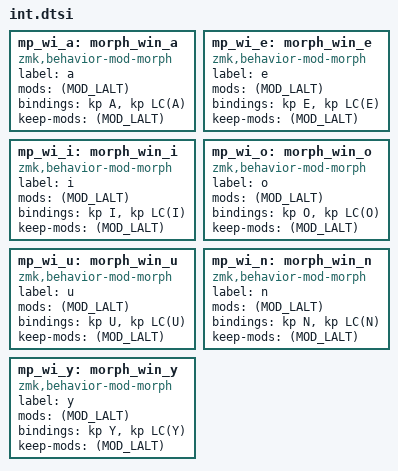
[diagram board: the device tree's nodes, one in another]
mp_wi_a: morph_win_a {
    compatible = "zmk,behavior-mod-morph";
    label = "a";
    #binding-cells = <0>;
    mods = <(MOD_LALT)>;
    bindings = <&kp A>, <&kp LC(A)>;
    keep-mods = <(MOD_LALT)>;
};

mp_wi_e: morph_win_e {
    compatible = "zmk,behavior-mod-morph";
    label = "e";
    #binding-cells = <0>;
    mods = <(MOD_LALT)>;
    bindings = <&kp E>, <&kp LC(E)>;
    keep-mods = <(MOD_LALT)>;
};

mp_wi_i: morph_win_i {
    compatible = "zmk,behavior-mod-morph";
    label = "i";
    #binding-cells = <0>;
    mods = <(MOD_LALT)>;
    bindings = <&kp I>, <&kp LC(I)>;
    keep-mods = <(MOD_LALT)>;
};

mp_wi_o: morph_win_o {
    compatible = "zmk,behavior-mod-morph";
    label = "o";
    #binding-cells = <0>;
    mods = <(MOD_LALT)>;
    bindings = <&kp O>, <&kp LC(O)>;
    keep-mods = <(MOD_LALT)>;
};

mp_wi_u: morph_win_u {
    compatible = "zmk,behavior-mod-morph";
    label = "u";
    #binding-cells = <0>;
    mods = <(MOD_LALT)>;
    bindings = <&kp U>, <&kp LC(U)>;
    keep-mods = <(MOD_LALT)>;
};

mp_wi_n: morph_win_n {
    compatible = "zmk,behavior-mod-morph";
    label = "n";
    #binding-cells = <0>;
    mods = <(MOD_LALT)>;
    bindings = <&kp N>, <&kp LC(N)>;
    keep-mods = <(MOD_LALT)>;
};

mp_wi_y: morph_win_y {
    compatible = "zmk,behavior-mod-morph";
    label = "y";
    #binding-cells = <0>;
    mods = <(MOD_LALT)>;
    bindings = <&kp Y>, <&kp LC(Y)>;
    keep-mods = <(MOD_LALT)>;
};
